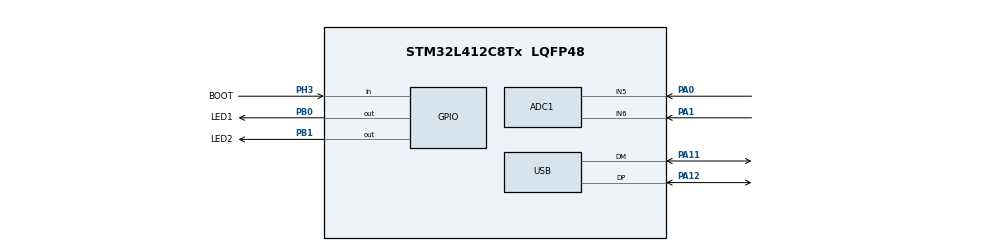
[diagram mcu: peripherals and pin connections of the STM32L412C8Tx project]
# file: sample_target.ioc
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ADC1.Channel-0\#ChannelRegularConversion=ADC_CHANNEL_5
ADC1.NbrOfConversionFlag=1
ADC1.OffsetNumber-0\#ChannelRegularConversion=ADC_OFFSET_NONE
ADC1.Rank-0\#ChannelRegularConversion=1
ADC1.SamplingTime-0\#ChannelRegularConversion=ADC_SAMPLETIME_2CYCLES_5
ADC1.master=1
Mcu.Family=STM32L4
Mcu.Name=STM32L412C8Tx
Mcu.Package=LQFP48
NVIC.PriorityGroup=NVIC_PRIORITYGROUP_4
NVIC.USB_IRQn=true\:0\:0\:false\:false\:true\:false\:true
PA0.Signal=ADCx_IN5
PA1.Signal=ADCx_IN6
PA11.Mode=Device
PA11.Signal=USB_DM
PA12.Mode=Device
PA12.Signal=USB_DP
PB0.GPIO_Label=LED1
PB0.Signal=GPIO_Output
PB1.GPIO_Label=LED2
PB1.Signal=GPIO_Output
PH3-BOOT0\ (BOOT0).GPIO_Label=BOOT
PH3-BOOT0\ (BOOT0).Signal=GPIO_Input
ProjectManager.HeapSize=0x200
ProjectManager.StackSize=0x400
ProjectManager.TargetToolchain=Makefile
RCC.ADCFreq_Value=80000000
RCC.AHBFreq_Value=80000000
RCC.APB1Freq_Value=80000000
RCC.APB1TimFreq_Value=80000000
RCC.APB2Freq_Value=80000000
RCC.APB2TimFreq_Value=80000000
RCC.CortexFreq_Value=80000000
RCC.HCLKFreq_Value=80000000
RCC.HSE_VALUE=8000000
RCC.HSI48_VALUE=48000000
RCC.HSI_VALUE=16000000
RCC.LSE_VALUE=32768
RCC.MSIClockRange=RCC_MSIRANGE_11
RCC.MSI_VALUE=48000000
RCC.PLLN=10
RCC.PLLSourceVirtual=RCC_PLLSOURCE_HSI
RCC.SYSCLKFreq_VALUE=80000000
RCC.SYSCLKSource=RCC_SYSCLKSOURCE_PLLCLK
RCC.USBFreq_Value=48000000
RCC.VCOOutputFreq_Value=160000000
SH.ADCx_IN5.0=ADC1_IN5,IN5-Single-Ended
SH.ADCx_IN6.0=ADC1_IN6,IN6-Single-Ended
USB_DEVICE.CLASS_NAME_FS=CDC
USB_DEVICE.VirtualMode=Cdc
USB_DEVICE.VirtualModeFS=Cdc_FS
VP_USB_DEVICE_VS_USB_DEVICE_CDC_FS.Mode=CDC_FS
board=custom

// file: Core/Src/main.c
/* USER CODE BEGIN Header */
/**
  ******************************************************************************
  * @file           : main.c
  * @brief          : Main program body
  ******************************************************************************
  * @attention
  *
  * Copyright (c) 2022 STMicroelectronics.
  * All rights reserved.
  *
  * This software is licensed under terms that can be found in the LICENSE file
  * in the root directory of this software component.
  * If no LICENSE file comes with this software, it is provided AS-IS.
  *
  ******************************************************************************
  */
/* USER CODE END Header */
#include "main.h"
#include "adc.h"
#include "usb_device.h"
#include "gpio.h"

void SystemClock_Config(void);

int main(void)
{

  /* MCU Configuration--------------------------------------------------------*/

  /* Reset of all peripherals, Initializes the Flash interface and the Systick. */
  HAL_Init();

  /* Configure the system clock */
  SystemClock_Config();

  /* Initialize all configured peripherals */
  MX_GPIO_Init();
  MX_ADC1_Init();
  MX_USB_DEVICE_Init();

  /* Infinite loop */
  while (1)
  {

    /* USER CODE BEGIN 3 */
    LL_GPIO_ResetOutputPin(LED1_GPIO_Port, LED1_Pin);
    LL_GPIO_SetOutputPin(LED2_GPIO_Port, LED2_Pin);
    HAL_Delay(500);
    LL_GPIO_SetOutputPin(LED1_GPIO_Port, LED1_Pin);
    LL_GPIO_ResetOutputPin(LED2_GPIO_Port, LED2_Pin);
    HAL_Delay(500);
  }
  /* USER CODE END 3 */
}

void SystemClock_Config(void)
{
  LL_FLASH_SetLatency(LL_FLASH_LATENCY_4);
  while(LL_FLASH_GetLatency()!= LL_FLASH_LATENCY_4)
  {
  }
  LL_PWR_SetRegulVoltageScaling(LL_PWR_REGU_VOLTAGE_SCALE1);
  LL_RCC_HSI_Enable();

   /* Wait till HSI is ready */
  while(LL_RCC_HSI_IsReady() != 1)
  {

  }
  LL_RCC_HSI_SetCalibTrimming(64);
  LL_RCC_MSI_Enable();

   /* Wait till MSI is ready */
  while(LL_RCC_MSI_IsReady() != 1)
  {

  }
  LL_RCC_MSI_EnableRangeSelection();
  LL_RCC_MSI_SetRange(LL_RCC_MSIRANGE_11);
  LL_RCC_MSI_SetCalibTrimming(0);
  LL_RCC_PLL_ConfigDomain_SYS(LL_RCC_PLLSOURCE_HSI, LL_RCC_PLLM_DIV_1, 10, LL_RCC_PLLR_DIV_2);
  LL_RCC_PLL_EnableDomain_SYS();
  LL_RCC_PLL_Enable();

   /* Wait till PLL is ready */
  while(LL_RCC_PLL_IsReady() != 1)
  {

  }
  LL_RCC_SetSysClkSource(LL_RCC_SYS_CLKSOURCE_PLL);

   /* Wait till System clock is ready */
  while(LL_RCC_GetSysClkSource() != LL_RCC_SYS_CLKSOURCE_STATUS_PLL)
  {

  }
  LL_RCC_SetAHBPrescaler(LL_RCC_SYSCLK_DIV_1);
  LL_RCC_SetAPB1Prescaler(LL_RCC_APB1_DIV_1);
  LL_RCC_SetAPB2Prescaler(LL_RCC_APB2_DIV_1);
  LL_SetSystemCoreClock(80000000);

   /* Update the time base */
  if (HAL_InitTick (TICK_INT_PRIORITY) != HAL_OK)
  {
    Error_Handler();
  }
}

void Error_Handler(void)
{
  __disable_irq();
  while (1)
  {
  }
}
